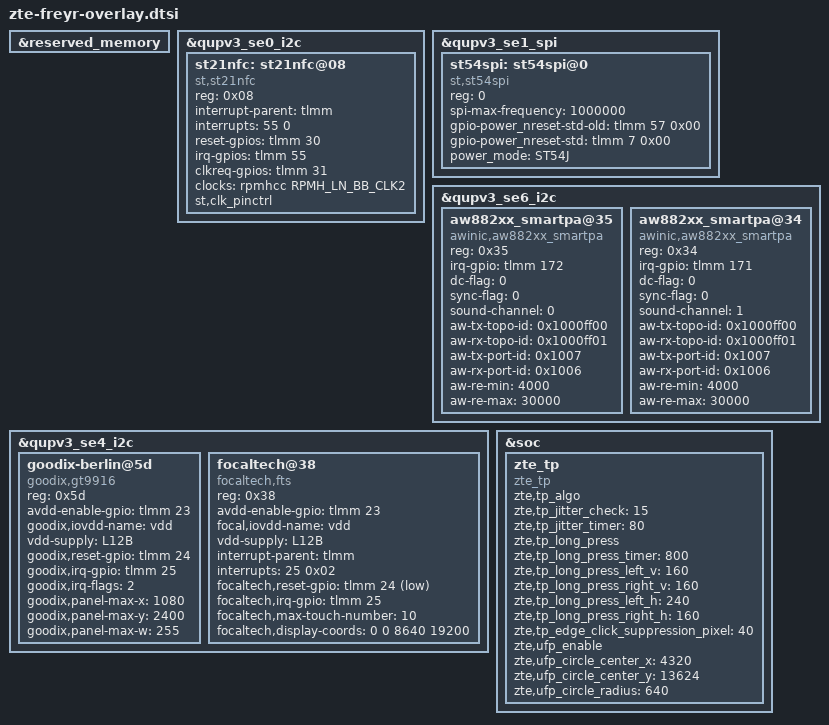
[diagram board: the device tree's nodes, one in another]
/* dtsi for freyr board (PQ82A01)*/
#include <dt-bindings/clock/qcom,rpmh.h>
#include "../zte-fingerprint-axon-goodix.dtsi"

&reserved_memory {
};

&qupv3_se0_i2c {
	 status = "ok";
	 /delete-node/ nq@28;
	 st21nfc: st21nfc@08 {
			 compatible = "st,st21nfc";
			 reg = <0x08>;
			 interrupt-parent = <&tlmm>;
			 interrupts = <55  0>;
			 reset-gpios = <&tlmm 30 0x00>;
			 irq-gpios = <&tlmm 55 0x00>;
			 // pidle-gpios = <&tlmm 48 0x00>;
			 clkreq-gpios = <&tlmm 31 0x00>;
			 clocks = <&rpmhcc RPMH_LN_BB_CLK2>;
			 clock-names = "nfc_ref_clk";
			 st,clk_pinctrl;
			 status = "ok";
	 };
};

&qupv3_se1_spi {
	 status = "ok";
	 st54spi: st54spi@0 {
			 compatible = "st,st54spi";
			 reg = <0>;
			 spi-max-frequency = <1000000>;
			 /* gpio used as SE_PWR_REQ or SE_nRESET */
			 gpio-power_nreset-std-old = <&tlmm 57 0x00>;
			 gpio-power_nreset-std = <&tlmm 7 0x00>;

			 /* Power management mode: none, ST54H (default), ST54J */
			 power_mode = "ST54J";

			 //pinctrl-names = "qupv3_se1_spi_sleep", "qupv3_se1_spi_active";
			 //pinctrl-0 = <&qupv3_se1_spi_sleep>;
			 //pinctrl-1 = <&qupv3_se1_spi_active>;
			 status = "ok";
	 };
};

&qupv3_se6_i2c {
	status = "okay";
	/* AWINIC AW882XX Smart PA */
	aw882xx_smartpa@35 {
		compatible = "awinic,aw882xx_smartpa";
		reg = <0x35>;
		irq-gpio = <&tlmm 172 0x2008>;
		dc-flag = <0>;
		sync-flag = <0>;
		sound-channel = <0>;
		aw-tx-topo-id = <0x1000ff00>;
		aw-rx-topo-id = <0x1000ff01>;
		aw-tx-port-id = <0x1007>;
		aw-rx-port-id = <0x1006>;
		aw-re-min = <4000>;
		aw-re-max= <30000>;
		/*aw-cali-mode = "none";*/
	};
	aw882xx_smartpa@34 {
		compatible = "awinic,aw882xx_smartpa";
		reg = <0x34>;
		irq-gpio = <&tlmm 171 0x2008>;
		dc-flag = <0>;
		sync-flag = <0>;
		sound-channel = <1>;
		aw-tx-topo-id = <0x1000ff00>;
		aw-rx-topo-id = <0x1000ff01>;
		aw-tx-port-id = <0x1007>;
		aw-rx-port-id = <0x1006>;
		aw-re-min = <4000>;
		aw-re-max= <30000>;
		/*aw-cali-mode = "none";*/
	};
};
	/* AWINIC AW882XX Smart PA End */

&qupv3_se4_i2c {

	status = "ok";

	goodix-berlin@5d {
		compatible = "goodix,gt9916";
		reg = <0x5d>;
		avdd-enable-gpio = <&tlmm 23 0x0>;
		goodix,iovdd-name = "vdd";
		vdd-supply = <&L12B>;
		goodix,reset-gpio = <&tlmm 24 0x0>;
		goodix,irq-gpio = <&tlmm 25 0x2800>;
		goodix,irq-flags = <2>; /* 1:trigger rising, 2:trigger falling;*/
		goodix,panel-max-x = <1080>;
		goodix,panel-max-y = <2400>;
		goodix,panel-max-w = <255>;
	};
	focaltech@38{
		compatible = "focaltech,fts";
		reg = <0x38>;
		avdd-enable-gpio = <&tlmm 23 0x0>;
		focal,iovdd-name = "vdd";
		vdd-supply = <&L12B>;
		interrupt-parent = <&tlmm>;
		interrupts = <25 0x02>;
		focaltech,reset-gpio = <&tlmm 24 0x01>;
		focaltech,irq-gpio = <&tlmm 25 0x02>;
		focaltech,max-touch-number = <10>;
		focaltech,display-coords =  <0 0 8640 19200>;

		/*pinctrl-names = "pmx_ts_active","pmx_ts_suspend","pmx_ts_release";
		pinctrl-0 = <&ts_int_active &ts_reset_active>;
		pinctrl-1 = <&ts_int_suspend &ts_reset_suspend>;
		pinctrl-2 = <&ts_release>;*/

		/*
		focaltech,have-key;
		focaltech,key-number = <3>;
		focaltech,keys = <139 102 158>;
		focaltech,key-x-coords = <200 600 800>;
		focaltech,key-y-coords = <2000 2000 2000>;
		*/
	};
};

&soc {
	zte_tp:zte_tp {
		compatible = "zte_tp";
		zte,tp_algo;
		zte,tp_jitter_check = <15>;
		zte,tp_jitter_timer = <80>;
		zte,tp_long_press;
		zte,tp_long_press_timer = <800>;
		zte,tp_long_press_left_v = <160>;
		zte,tp_long_press_right_v = <160>;
		zte,tp_long_press_left_h = <240>; /*camera */
		zte,tp_long_press_right_h = <160>; /*charger */
		zte,tp_edge_click_suppression_pixel = <40>;
		zte,ufp_enable;
		zte,ufp_circle_center_x = <4320>;
		zte,ufp_circle_center_y = <13624>;
		zte,ufp_circle_radius = <640>;
	};

};

